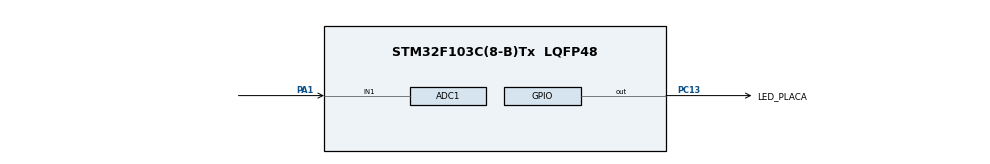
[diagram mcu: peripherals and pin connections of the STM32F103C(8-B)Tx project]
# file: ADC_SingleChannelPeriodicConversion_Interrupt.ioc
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ADC1.Channel-0\#ChannelRegularConversion=ADC_CHANNEL_1
ADC1.ExternalTrigConv=ADC_EXTERNALTRIGCONV_T3_TRGO
ADC1.NbrOfConversionFlag=1
ADC1.Rank-0\#ChannelRegularConversion=1
ADC1.SamplingTime-0\#ChannelRegularConversion=ADC_SAMPLETIME_1CYCLE_5
ADC1.master=1
Mcu.Family=STM32F1
Mcu.Name=STM32F103C(8-B)Tx
Mcu.Package=LQFP48
NVIC.ADC1_2_IRQn=true\:0\:0\:false\:false\:true\:true\:true\:true
NVIC.PriorityGroup=NVIC_PRIORITYGROUP_4
PA1.Signal=ADCx_IN1
PA13.Mode=Serial_Wire
PA13.Signal=SYS_JTMS-SWDIO
PA14.Mode=Serial_Wire
PA14.Signal=SYS_JTCK-SWCLK
PC13-TAMPER-RTC.GPIO_Label=LED_PLACA
PC13-TAMPER-RTC.Signal=GPIO_Output
ProjectManager.HeapSize=0x200
ProjectManager.StackSize=0x400
ProjectManager.TargetToolchain=STM32CubeIDE
RCC.APB1Freq_Value=8000000
RCC.APB2Freq_Value=8000000
SH.ADCx_IN1.0=ADC1_IN1,IN1
TIM3.Channel-PWM\ Generation1\ No\ Output=TIM_CHANNEL_1
TIM3.Period=9999
TIM3.Prescaler=799
TIM3.Pulse-PWM\ Generation1\ No\ Output=5000
TIM3.TIM_MasterOutputTrigger=TIM_TRGO_UPDATE
VP_TIM3_VS_ClockSourceINT.Mode=Internal
VP_TIM3_VS_no_output1.Mode=PWM Generation1 No Output
board=custom

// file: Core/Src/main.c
/* USER CODE BEGIN Header */
/**
  ******************************************************************************
  * @file           : main.c
  * @brief          : Main program body
  ******************************************************************************
  * @attention
  *
  * Copyright (c) 2022 STMicroelectronics.
  * All rights reserved.
  *
  * This software is licensed under terms that can be found in the LICENSE file
  * in the root directory of this software component.
  * If no LICENSE file comes with this software, it is provided AS-IS.
  *
  ******************************************************************************
  */
/* USER CODE END Header */
#include "main.h"

ADC_HandleTypeDef hadc1;

TIM_HandleTypeDef htim3;

void SystemClock_Config(void);
static void MX_GPIO_Init(void);
static void MX_ADC1_Init(void);
static void MX_TIM3_Init(void);

/* USER CODE BEGIN 0 */
uint32_t adc_val;
uint32_t dma_buff;
/* USER CODE END 0 */

int main(void)
{

  /* MCU Configuration--------------------------------------------------------*/

  /* Reset of all peripherals, Initializes the Flash interface and the Systick. */
  HAL_Init();

  /* Configure the system clock */
  SystemClock_Config();

  /* Initialize all configured peripherals */
  MX_GPIO_Init();
  MX_ADC1_Init();
  MX_TIM3_Init();
  /* USER CODE BEGIN 2 */

  // inicia a utilização do ADC
  if(HAL_ADC_Start_DMA(&hadc1, &dma_buff, 1) != HAL_OK){
	  Error_Handler();
  }

  // inicia a utilização de interrupção para a conversão ADC
  if(HAL_ADC_Start_IT(&hadc1) != HAL_OK){
	  Error_Handler();
  }

  HAL_TIM_PWM_Start(&htim3, TIM_CHANNEL_1);

  /* USER CODE END 2 */

  /* Infinite loop */
  while (1)
  {

    /* USER CODE BEGIN 3 */
	  _HAL_TIM_SET_COMPARE(&htim3, TIM_CHANNEL_1, dma_buff);
	  HAL_Delay(10);

  }
  /* USER CODE END 3 */
}

void SystemClock_Config(void)
{
  RCC_OscInitTypeDef RCC_OscInitStruct = {0};
  RCC_ClkInitTypeDef RCC_ClkInitStruct = {0};
  RCC_PeriphCLKInitTypeDef PeriphClkInit = {0};

  /** Initializes the RCC Oscillators according to the specified parameters
  * in the RCC_OscInitTypeDef structure.
  */
  RCC_OscInitStruct.OscillatorType = RCC_OSCILLATORTYPE_HSI;
  RCC_OscInitStruct.HSIState = RCC_HSI_ON;
  RCC_OscInitStruct.HSICalibrationValue = RCC_HSICALIBRATION_DEFAULT;
  RCC_OscInitStruct.PLL.PLLState = RCC_PLL_NONE;
  if (HAL_RCC_OscConfig(&RCC_OscInitStruct) != HAL_OK)
  {
    Error_Handler();
  }

  /** Initializes the CPU, AHB and APB buses clocks
  */
  RCC_ClkInitStruct.ClockType = RCC_CLOCKTYPE_HCLK|RCC_CLOCKTYPE_SYSCLK
                              |RCC_CLOCKTYPE_PCLK1|RCC_CLOCKTYPE_PCLK2;
  RCC_ClkInitStruct.SYSCLKSource = RCC_SYSCLKSOURCE_HSI;
  RCC_ClkInitStruct.AHBCLKDivider = RCC_SYSCLK_DIV1;
  RCC_ClkInitStruct.APB1CLKDivider = RCC_HCLK_DIV1;
  RCC_ClkInitStruct.APB2CLKDivider = RCC_HCLK_DIV1;

  if (HAL_RCC_ClockConfig(&RCC_ClkInitStruct, FLASH_LATENCY_0) != HAL_OK)
  {
    Error_Handler();
  }
  PeriphClkInit.PeriphClockSelection = RCC_PERIPHCLK_ADC;
  PeriphClkInit.AdcClockSelection = RCC_ADCPCLK2_DIV2;
  if (HAL_RCCEx_PeriphCLKConfig(&PeriphClkInit) != HAL_OK)
  {
    Error_Handler();
  }
}

static void MX_ADC1_Init(void)
{

  ADC_ChannelConfTypeDef sConfig = {0};

  /** Common config
  */
  hadc1.Instance = ADC1;
  hadc1.Init.ScanConvMode = ADC_SCAN_DISABLE;
  hadc1.Init.ContinuousConvMode = DISABLE;
  hadc1.Init.DiscontinuousConvMode = DISABLE;
  hadc1.Init.ExternalTrigConv = ADC_EXTERNALTRIGCONV_T3_TRGO;
  hadc1.Init.DataAlign = ADC_DATAALIGN_RIGHT;
  hadc1.Init.NbrOfConversion = 1;
  if (HAL_ADC_Init(&hadc1) != HAL_OK)
  {
    Error_Handler();
  }

  /** Configure Regular Channel
  */
  sConfig.Channel = ADC_CHANNEL_1;
  sConfig.Rank = ADC_REGULAR_RANK_1;
  sConfig.SamplingTime = ADC_SAMPLETIME_1CYCLE_5;
  if (HAL_ADC_ConfigChannel(&hadc1, &sConfig) != HAL_OK)
  {
    Error_Handler();
  }

}

static void MX_TIM3_Init(void)
{

  TIM_ClockConfigTypeDef sClockSourceConfig = {0};
  TIM_MasterConfigTypeDef sMasterConfig = {0};
  TIM_OC_InitTypeDef sConfigOC = {0};

  htim3.Instance = TIM3;
  htim3.Init.Prescaler = 799;
  htim3.Init.CounterMode = TIM_COUNTERMODE_UP;
  htim3.Init.Period = 9999;
  htim3.Init.ClockDivision = TIM_CLOCKDIVISION_DIV1;
  htim3.Init.AutoReloadPreload = TIM_AUTORELOAD_PRELOAD_DISABLE;
  if (HAL_TIM_Base_Init(&htim3) != HAL_OK)
  {
    Error_Handler();
  }
  sClockSourceConfig.ClockSource = TIM_CLOCKSOURCE_INTERNAL;
  if (HAL_TIM_ConfigClockSource(&htim3, &sClockSourceConfig) != HAL_OK)
  {
    Error_Handler();
  }
  if (HAL_TIM_PWM_Init(&htim3) != HAL_OK)
  {
    Error_Handler();
  }
  sMasterConfig.MasterOutputTrigger = TIM_TRGO_UPDATE;
  sMasterConfig.MasterSlaveMode = TIM_MASTERSLAVEMODE_DISABLE;
  if (HAL_TIMEx_MasterConfigSynchronization(&htim3, &sMasterConfig) != HAL_OK)
  {
    Error_Handler();
  }
  sConfigOC.OCMode = TIM_OCMODE_PWM1;
  sConfigOC.Pulse = 5000;
  sConfigOC.OCPolarity = TIM_OCPOLARITY_HIGH;
  sConfigOC.OCFastMode = TIM_OCFAST_DISABLE;
  if (HAL_TIM_PWM_ConfigChannel(&htim3, &sConfigOC, TIM_CHANNEL_1) != HAL_OK)
  {
    Error_Handler();
  }

}

static void MX_GPIO_Init(void)
{
  GPIO_InitTypeDef GPIO_InitStruct = {0};

  /* GPIO Ports Clock Enable */
  __HAL_RCC_GPIOC_CLK_ENABLE();
  __HAL_RCC_GPIOA_CLK_ENABLE();

  /*Configure GPIO pin Output Level */
  HAL_GPIO_WritePin(LED_PLACA_GPIO_Port, LED_PLACA_Pin, GPIO_PIN_RESET);

  /*Configure GPIO pin : LED_PLACA_Pin */
  GPIO_InitStruct.Pin = LED_PLACA_Pin;
  GPIO_InitStruct.Mode = GPIO_MODE_OUTPUT_PP;
  GPIO_InitStruct.Pull = GPIO_NOPULL;
  GPIO_InitStruct.Speed = GPIO_SPEED_FREQ_LOW;
  HAL_GPIO_Init(LED_PLACA_GPIO_Port, &GPIO_InitStruct);

}

/* USER CODE BEGIN 4 */
void HAL_ADC_ConvCpltCallback(ADC_HandleTypeDef *hadc){
	// lê o resultado da conversão
	adc_val = dma_buff;

	// dá o toggle do LED
	HAL_GPIO_TogglePin(LED_PLACA_GPIO_Port, LED_PLACA_Pin);
}
/* USER CODE END 4 */

void Error_Handler(void)
{
  __disable_irq();
  while (1)
  {
  }
}
